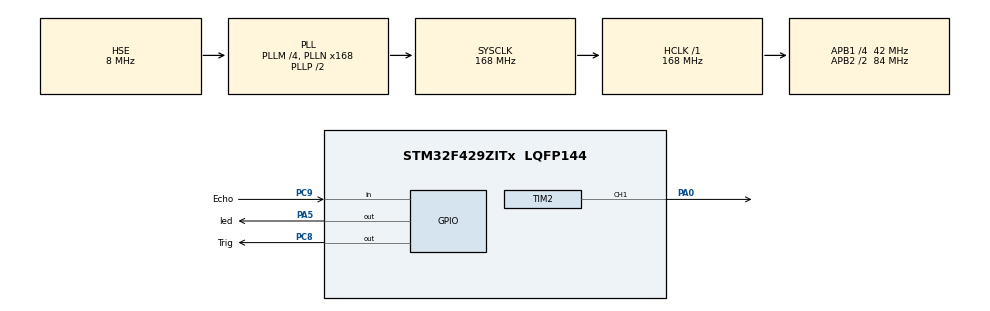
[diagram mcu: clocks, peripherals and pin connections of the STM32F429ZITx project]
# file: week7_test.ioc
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Mcu.Family=STM32F4
Mcu.Name=STM32F429ZITx
Mcu.Package=LQFP144
NVIC.PriorityGroup=NVIC_PRIORITYGROUP_4
NVIC.TIM2_IRQn=true\:0\:0\:false\:false\:true\:true\:true\:true
PA0/WKUP.Signal=S_TIM2_CH1_ETR
PA13.Mode=Serial_Wire
PA13.Signal=SYS_JTMS-SWDIO
PA14.Mode=Serial_Wire
PA14.Signal=SYS_JTCK-SWCLK
PA5.GPIO_Label=led
PA5.Signal=GPIO_Output
PC8.GPIO_Label=Trig
PC8.Signal=GPIO_Output
PC9.GPIO_Label=Echo
PC9.Signal=GPIO_Input
PH0/OSC_IN.Mode=HSE-External-Oscillator
PH0/OSC_IN.Signal=RCC_OSC_IN
PH1/OSC_OUT.Mode=HSE-External-Oscillator
PH1/OSC_OUT.Signal=RCC_OSC_OUT
ProjectManager.HeapSize=0x200
ProjectManager.StackSize=0x400
ProjectManager.TargetToolchain=STM32CubeIDE
RCC.48MHZClocksFreq_Value=48000000
RCC.AHBFreq_Value=168000000
RCC.APB1CLKDivider=RCC_HCLK_DIV4
RCC.APB1Freq_Value=42000000
RCC.APB1TimFreq_Value=84000000
RCC.APB2CLKDivider=RCC_HCLK_DIV2
RCC.APB2Freq_Value=84000000
RCC.APB2TimFreq_Value=168000000
RCC.CortexFreq_Value=168000000
RCC.HCLKFreq_Value=168000000
RCC.HSE_VALUE=8000000
RCC.HSI_VALUE=16000000
RCC.LSE_VALUE=32768
RCC.PLLM=4
RCC.PLLMUL=RCC_PLL_MUL9
RCC.PLLN=168
RCC.PLLQ=7
RCC.PLLSourceVirtual=RCC_PLLSOURCE_HSE
RCC.PRESCALERUSB=RCC_USBCLKSOURCE_PLL_DIV1_5
RCC.SYSCLKFreq_VALUE=168000000
RCC.SYSCLKSource=RCC_SYSCLKSOURCE_PLLCLK
RCC.SYSCLKSourceVirtual=RCC_SYSCLKSOURCE_PLLCLK
RCC.USBFreq_Value=48000000
RCC.VCOOutputFreq_Value=336000000
SH.S_TIM2_CH1_ETR.0=TIM2_CH1,PWM Generation1 CH1
TIM2.Channel-PWM\ Generation1\ CH1=TIM_CHANNEL_1
TIM2.Period=10000-1
TIM2.Prescaler=168
TIM7.Prescaler=84-1
VP_TIM2_VS_ClockSourceINT.Mode=Internal
VP_TIM7_VS_ClockSourceINT.Mode=Enable_Timer
board=NUCLEO-F429ZI

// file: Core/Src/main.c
/* USER CODE BEGIN Header */
/**
  ******************************************************************************
  * @file           : main.c
  * @brief          : Main program body
  ******************************************************************************
  * @attention
  *
  * Copyright (c) 2025 STMicroelectronics.
  * All rights reserved.
  *
  * This software is licensed under terms that can be found in the LICENSE file
  * in the root directory of this software component.
  * If no LICENSE file comes with this software, it is provided AS-IS.
  *
  ******************************************************************************
  */
/* USER CODE END Header */
#include "main.h"

TIM_HandleTypeDef htim2;
TIM_HandleTypeDef htim7;

void SystemClock_Config(void);
static void MX_GPIO_Init(void);
static void MX_TIM2_Init(void);
static void MX_TIM7_Init(void);

/* USER CODE BEGIN 0 */
void Set_Servo_Angle(TIM_HandleTypeDef *htim, uint32_t channel, uint8_t angle){
	//angle(0-180)to pulse width(250-1250 counts)
	//250 for 0.5ms(0 degree) and 1250 for 2.5ms(180 degree)
	uint32_t pulse_length = 250 +(angle *(1250-250)/180);
	__HAL_TIM_SET_COMPARE(htim, channel, pulse_length);
}
uint32_t distance = 0;
int triggered = 0;  // 初始狀態：未觸發
/* USER CODE END 0 */
void delay(uint32_t us){
	HAL_TIM_Base_Start(&htim7);
	while(__HAL_TIM_GET_COUNTER(&htim7)<us);
	HAL_TIM_Base_Stop(&htim7);
	__HAL_TIM_SET_COUNTER(&htim7,0);
}
int main(void)
{

  /* MCU Configuration--------------------------------------------------------*/

  /* Reset of all peripherals, Initializes the Flash interface and the Systick. */
  HAL_Init();

  /* Configure the system clock */
  SystemClock_Config();

  /* Initialize all configured peripherals */
  MX_GPIO_Init();
  MX_TIM2_Init();
  MX_TIM7_Init();
  /* USER CODE BEGIN 2 */
  HAL_TIM_PWM_Start(&htim2, TIM_CHANNEL_1);

  /* USER CODE END 2 */
  float time = 0;
  /* Infinite loop */
  while (1)
   {

	   // 發出 10us 脈波
	   HAL_GPIO_WritePin(GPIOC, GPIO_PIN_8, GPIO_PIN_SET);
	   delay(10);
	   HAL_GPIO_WritePin(GPIOC, GPIO_PIN_8, GPIO_PIN_RESET);

	   // 等待 Echo
	   while (HAL_GPIO_ReadPin(GPIOC, GPIO_PIN_9) == GPIO_PIN_RESET);
	   HAL_TIM_Base_Start(&htim7);

	   while (HAL_GPIO_ReadPin(GPIOC, GPIO_PIN_9) == GPIO_PIN_SET);
	   HAL_TIM_Base_Stop(&htim7);

	   // 計算距離
	   time = __HAL_TIM_GET_COUNTER(&htim7);
	   __HAL_TIM_SET_COUNTER(&htim7, 0);
	   distance = time / 58.0f;
	   HAL_Delay(700);
	    if (distance < 20 && triggered == 0) {
	        // 例如開 LED、伺服馬達等等
	    	triggered = 1;  // ✅ 避免重複觸發
	  	  for (uint8_t angle = 0; angle <= 180; angle += 30){
	  		  Set_Servo_Angle(&htim2, TIM_CHANNEL_1, angle);
	  		  HAL_Delay(300);
	  		  HAL_GPIO_WritePin(GPIOA, GPIO_PIN_5, GPIO_PIN_SET);

	  	  }

	        for (int i = 0; i < 4; i++) {
	            HAL_GPIO_WritePin(GPIOA, GPIO_PIN_5, GPIO_PIN_SET);
	            HAL_Delay(500);
	            HAL_GPIO_WritePin(GPIOA, GPIO_PIN_5, GPIO_PIN_RESET);
	            HAL_Delay(500);
	        }

	  	  HAL_Delay(500);
	  	  for (uint8_t angle = 180; angle > 0; angle -= 30){
	  		  Set_Servo_Angle(&htim2, TIM_CHANNEL_1, angle);
	  		  HAL_Delay(300);
	  		  HAL_GPIO_WritePin(GPIOA, GPIO_PIN_5, GPIO_PIN_SET);
	  	  }
	  	 Set_Servo_Angle(&htim2, TIM_CHANNEL_1, 0);  // 保險回到 0
	    }
	    else if(distance >= 20){
	    		triggered = 0;
	  		  HAL_GPIO_WritePin(GPIOA, GPIO_PIN_5, GPIO_PIN_SET);

	    }
	    HAL_Delay(500);
   /* USER CODE BEGIN 3 */
    /* USER CODE BEGIN 3 */

   }
  /* USER CODE END 3 */
}

void SystemClock_Config(void)
{
  RCC_OscInitTypeDef RCC_OscInitStruct = {0};
  RCC_ClkInitTypeDef RCC_ClkInitStruct = {0};

  /** Configure the main internal regulator output voltage
  */
  __HAL_RCC_PWR_CLK_ENABLE();
  __HAL_PWR_VOLTAGESCALING_CONFIG(PWR_REGULATOR_VOLTAGE_SCALE1);

  /** Initializes the RCC Oscillators according to the specified parameters
  * in the RCC_OscInitTypeDef structure.
  */
  RCC_OscInitStruct.OscillatorType = RCC_OSCILLATORTYPE_HSE;
  RCC_OscInitStruct.HSEState = RCC_HSE_ON;
  RCC_OscInitStruct.PLL.PLLState = RCC_PLL_ON;
  RCC_OscInitStruct.PLL.PLLSource = RCC_PLLSOURCE_HSE;
  RCC_OscInitStruct.PLL.PLLM = 4;
  RCC_OscInitStruct.PLL.PLLN = 168;
  RCC_OscInitStruct.PLL.PLLP = RCC_PLLP_DIV2;
  RCC_OscInitStruct.PLL.PLLQ = 7;
  if (HAL_RCC_OscConfig(&RCC_OscInitStruct) != HAL_OK)
  {
    Error_Handler();
  }

  /** Initializes the CPU, AHB and APB buses clocks
  */
  RCC_ClkInitStruct.ClockType = RCC_CLOCKTYPE_HCLK|RCC_CLOCKTYPE_SYSCLK
                              |RCC_CLOCKTYPE_PCLK1|RCC_CLOCKTYPE_PCLK2;
  RCC_ClkInitStruct.SYSCLKSource = RCC_SYSCLKSOURCE_PLLCLK;
  RCC_ClkInitStruct.AHBCLKDivider = RCC_SYSCLK_DIV1;
  RCC_ClkInitStruct.APB1CLKDivider = RCC_HCLK_DIV4;
  RCC_ClkInitStruct.APB2CLKDivider = RCC_HCLK_DIV2;

  if (HAL_RCC_ClockConfig(&RCC_ClkInitStruct, FLASH_LATENCY_5) != HAL_OK)
  {
    Error_Handler();
  }
}

static void MX_TIM2_Init(void)
{

  TIM_ClockConfigTypeDef sClockSourceConfig = {0};
  TIM_MasterConfigTypeDef sMasterConfig = {0};
  TIM_OC_InitTypeDef sConfigOC = {0};

  htim2.Instance = TIM2;
  htim2.Init.Prescaler = 168;
  htim2.Init.CounterMode = TIM_COUNTERMODE_UP;
  htim2.Init.Period = 10000-1;
  htim2.Init.ClockDivision = TIM_CLOCKDIVISION_DIV1;
  htim2.Init.AutoReloadPreload = TIM_AUTORELOAD_PRELOAD_DISABLE;
  if (HAL_TIM_Base_Init(&htim2) != HAL_OK)
  {
    Error_Handler();
  }
  sClockSourceConfig.ClockSource = TIM_CLOCKSOURCE_INTERNAL;
  if (HAL_TIM_ConfigClockSource(&htim2, &sClockSourceConfig) != HAL_OK)
  {
    Error_Handler();
  }
  if (HAL_TIM_PWM_Init(&htim2) != HAL_OK)
  {
    Error_Handler();
  }
  sMasterConfig.MasterOutputTrigger = TIM_TRGO_RESET;
  sMasterConfig.MasterSlaveMode = TIM_MASTERSLAVEMODE_DISABLE;
  if (HAL_TIMEx_MasterConfigSynchronization(&htim2, &sMasterConfig) != HAL_OK)
  {
    Error_Handler();
  }
  sConfigOC.OCMode = TIM_OCMODE_PWM1;
  sConfigOC.Pulse = 0;
  sConfigOC.OCPolarity = TIM_OCPOLARITY_HIGH;
  sConfigOC.OCFastMode = TIM_OCFAST_DISABLE;
  if (HAL_TIM_PWM_ConfigChannel(&htim2, &sConfigOC, TIM_CHANNEL_1) != HAL_OK)
  {
    Error_Handler();
  }
  HAL_TIM_MspPostInit(&htim2);

}

static void MX_TIM7_Init(void)
{

  TIM_MasterConfigTypeDef sMasterConfig = {0};

  htim7.Instance = TIM7;
  htim7.Init.Prescaler = 84-1;
  htim7.Init.CounterMode = TIM_COUNTERMODE_UP;
  htim7.Init.Period = 65535;
  htim7.Init.AutoReloadPreload = TIM_AUTORELOAD_PRELOAD_DISABLE;
  if (HAL_TIM_Base_Init(&htim7) != HAL_OK)
  {
    Error_Handler();
  }
  sMasterConfig.MasterOutputTrigger = TIM_TRGO_RESET;
  sMasterConfig.MasterSlaveMode = TIM_MASTERSLAVEMODE_DISABLE;
  if (HAL_TIMEx_MasterConfigSynchronization(&htim7, &sMasterConfig) != HAL_OK)
  {
    Error_Handler();
  }

}

static void MX_GPIO_Init(void)
{
  GPIO_InitTypeDef GPIO_InitStruct = {0};

  /* GPIO Ports Clock Enable */
  __HAL_RCC_GPIOH_CLK_ENABLE();
  __HAL_RCC_GPIOA_CLK_ENABLE();
  __HAL_RCC_GPIOC_CLK_ENABLE();

  /*Configure GPIO pin Output Level */
  HAL_GPIO_WritePin(led_GPIO_Port, led_Pin, GPIO_PIN_RESET);

  /*Configure GPIO pin Output Level */
  HAL_GPIO_WritePin(Trig_GPIO_Port, Trig_Pin, GPIO_PIN_RESET);

  /*Configure GPIO pin : led_Pin */
  GPIO_InitStruct.Pin = led_Pin;
  GPIO_InitStruct.Mode = GPIO_MODE_OUTPUT_PP;
  GPIO_InitStruct.Pull = GPIO_NOPULL;
  GPIO_InitStruct.Speed = GPIO_SPEED_FREQ_LOW;
  HAL_GPIO_Init(led_GPIO_Port, &GPIO_InitStruct);

  /*Configure GPIO pin : Trig_Pin */
  GPIO_InitStruct.Pin = Trig_Pin;
  GPIO_InitStruct.Mode = GPIO_MODE_OUTPUT_PP;
  GPIO_InitStruct.Pull = GPIO_NOPULL;
  GPIO_InitStruct.Speed = GPIO_SPEED_FREQ_LOW;
  HAL_GPIO_Init(Trig_GPIO_Port, &GPIO_InitStruct);

  /*Configure GPIO pin : Echo_Pin */
  GPIO_InitStruct.Pin = Echo_Pin;
  GPIO_InitStruct.Mode = GPIO_MODE_INPUT;
  GPIO_InitStruct.Pull = GPIO_NOPULL;
  HAL_GPIO_Init(Echo_GPIO_Port, &GPIO_InitStruct);

}

void Error_Handler(void)
{
  __disable_irq();
  while (1)
  {
  }
}
